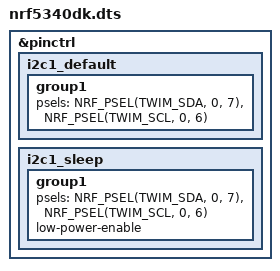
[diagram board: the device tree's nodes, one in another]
&pinctrl {
    i2c1_default: i2c1_default {
        group1 {
            psels = <NRF_PSEL(TWIM_SDA, 0, 7)>,
                    <NRF_PSEL(TWIM_SCL, 0, 6)>;
        };
    };

    i2c1_sleep: i2c1_sleep {
        group1 {
            psels = <NRF_PSEL(TWIM_SDA, 0, 7)>,
                    <NRF_PSEL(TWIM_SCL, 0, 6)>;
            low-power-enable;
        };
    };
};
